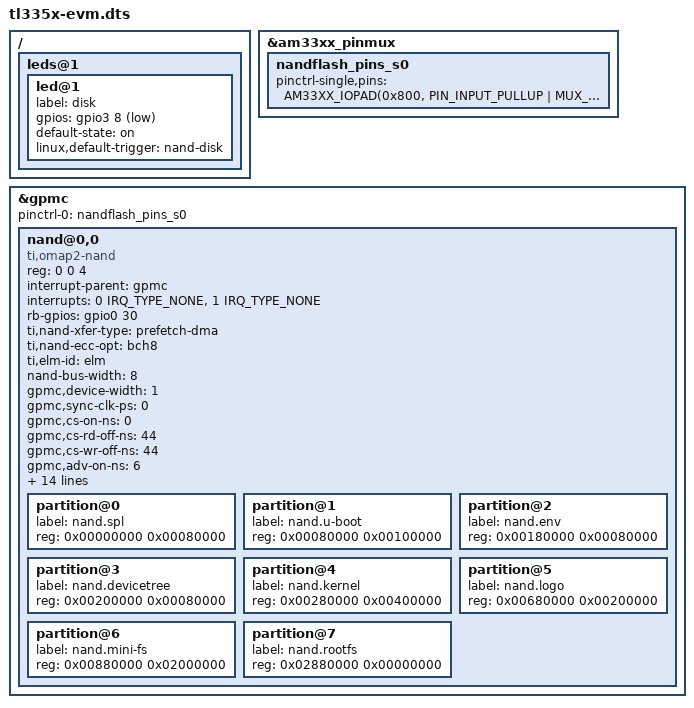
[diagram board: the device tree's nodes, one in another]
/*
 * Copyright (C) 2015 GuangZhou Tronlong co., LTD - http://www.tronlong.com
 *
 * This program is free software; you can redistribute it and/or modify
 * it under the terms of the GNU General Public License version 2 as
 * published by the Free Software Foundation.
 */

/* Common device tree for TL335x-EVM board */

#include "tl335x-evm-common.dts"

/ {
	leds@1 {
		led@1 {
			label = "disk";
			gpios = <&gpio3 8 GPIO_ACTIVE_LOW>;
			default-state = "on";
			linux,default-trigger = "nand-disk";
		};
	};
};

&am33xx_pinmux {
	nandflash_pins_s0: nandflash_pins_s0 {
		pinctrl-single,pins = <
			AM33XX_IOPAD(0x800, PIN_INPUT_PULLUP | MUX_MODE0)	/* gpmc_ad0.gpmc_ad0 */
			AM33XX_IOPAD(0x804, PIN_INPUT_PULLUP | MUX_MODE0)	/* gpmc_ad1.gpmc_ad1 */
			AM33XX_IOPAD(0x808, PIN_INPUT_PULLUP | MUX_MODE0)	/* gpmc_ad2.gpmc_ad2 */
			AM33XX_IOPAD(0x80c, PIN_INPUT_PULLUP | MUX_MODE0)	/* gpmc_ad3.gpmc_ad3 */
			AM33XX_IOPAD(0x810, PIN_INPUT_PULLUP | MUX_MODE0)	/* gpmc_ad4.gpmc_ad4 */
			AM33XX_IOPAD(0x814, PIN_INPUT_PULLUP | MUX_MODE0)	/* gpmc_ad5.gpmc_ad5 */
			AM33XX_IOPAD(0x818, PIN_INPUT_PULLUP | MUX_MODE0)	/* gpmc_ad6.gpmc_ad6 */
			AM33XX_IOPAD(0x81c, PIN_INPUT_PULLUP | MUX_MODE0)	/* gpmc_ad7.gpmc_ad7 */
			AM33XX_IOPAD(0x870, PIN_INPUT_PULLUP | MUX_MODE7)	/* gpmc_wait0.gpio0_30 */
			/* AM33XX_IOPAD(0x874, PIN_INPUT_PULLUP | MUX_MODE7)	/* gpmc_wpn.gpio0_30 */
			AM33XX_IOPAD(0x87c, PIN_OUTPUT | MUX_MODE0)	/* gpmc_csn0.gpmc_csn0  */
			AM33XX_IOPAD(0x890, PIN_OUTPUT | MUX_MODE0)	/* gpmc_advn_ale.gpmc_advn_ale */
			AM33XX_IOPAD(0x894, PIN_OUTPUT | MUX_MODE0)	/* gpmc_oen_ren.gpmc_oen_ren */
			AM33XX_IOPAD(0x898, PIN_OUTPUT | MUX_MODE0)	/* gpmc_wen.gpmc_wen */
			AM33XX_IOPAD(0x89c, PIN_OUTPUT | MUX_MODE0)	/* gpmc_be0n_cle.gpmc_be0n_cle */
		>;
	};
};

&gpmc {
	/* these are the same mios with emmc,
	* so emmc should be disabled when using nand*/
	status = "okay";
	pinctrl-names = "default";
	pinctrl-0 = <&nandflash_pins_s0>;
	ranges = <0 0 0x08000000 0x1000000>;	/* CS0: 16MB for NAND */
	nand@0,0 {
		compatible = "ti,omap2-nand";
		reg = <0 0 4>;	/* CS0, offset 0, IO size 4 */
		interrupt-parent = <&gpmc>;
		interrupts = <0 IRQ_TYPE_NONE>,	/* fifoevent */
					<1 IRQ_TYPE_NONE>;	/* termcount */
		rb-gpios = <&gpio0 30 GPIO_ACTIVE_HIGH>;	/* gpio0_30 */
		ti,nand-xfer-type = "prefetch-dma";
		ti,nand-ecc-opt = "bch8";
		ti,elm-id = <&elm>;
		nand-bus-width = <8>;
		gpmc,device-width = <1>;
		gpmc,sync-clk-ps = <0>;
		gpmc,cs-on-ns = <0>;
		gpmc,cs-rd-off-ns = <44>;
		gpmc,cs-wr-off-ns = <44>;
		gpmc,adv-on-ns = <6>;
		gpmc,adv-rd-off-ns = <34>;
		gpmc,adv-wr-off-ns = <44>;
		gpmc,we-on-ns = <0>;
		gpmc,we-off-ns = <40>;
		gpmc,oe-on-ns = <0>;
		gpmc,oe-off-ns = <54>;
		gpmc,access-ns = <64>;
		gpmc,rd-cycle-ns = <82>;
		gpmc,wr-cycle-ns = <82>;
		gpmc,bus-turnaround-ns = <0>;
		gpmc,cycle2cycle-delay-ns = <0>;
		gpmc,clk-activation-ns = <0>;
		gpmc,wr-access-ns = <40>;
		gpmc,wr-data-mux-bus-ns = <0>;
		/* MTD partition table */
		/* All SPL-* partitions are sized to minimal length
		* which can be independently programmable. For
		* NAND flash this is equal to size of erase-block */
		#address-cells = <1>;
		#size-cells = <1>;
		partition@0 {
			label = "nand.spl";
			reg = <0x00000000 0x00080000>;	/* 512KB */
		};

		partition@1 {
			label = "nand.u-boot";
			reg = <0x00080000 0x00100000>;	/* 1MB */
		};

		partition@2 {
			label = "nand.env";
			reg = <0x00180000 0x00080000>;	/* 512KB */
		};

		partition@3 {
			label = "nand.devicetree";
			reg = <0x00200000 0x00080000>;	/* 512KB */
		};

		partition@4 {
			label = "nand.kernel";
			reg = <0x00280000 0x00400000>;	/* 4MB */
		};

		partition@5 {
			label = "nand.logo";
			reg = <0x00680000 0x00200000>;	/* 2MB */
		};

		partition@6 {
			label = "nand.mini-fs";
			reg = <0x00880000 0x02000000>;	/* 32MB */
		};

		partition@7 {
			label = "nand.rootfs";
			reg = <0x02880000 0x00000000>;	/* 471MB */
		};
	};
};
